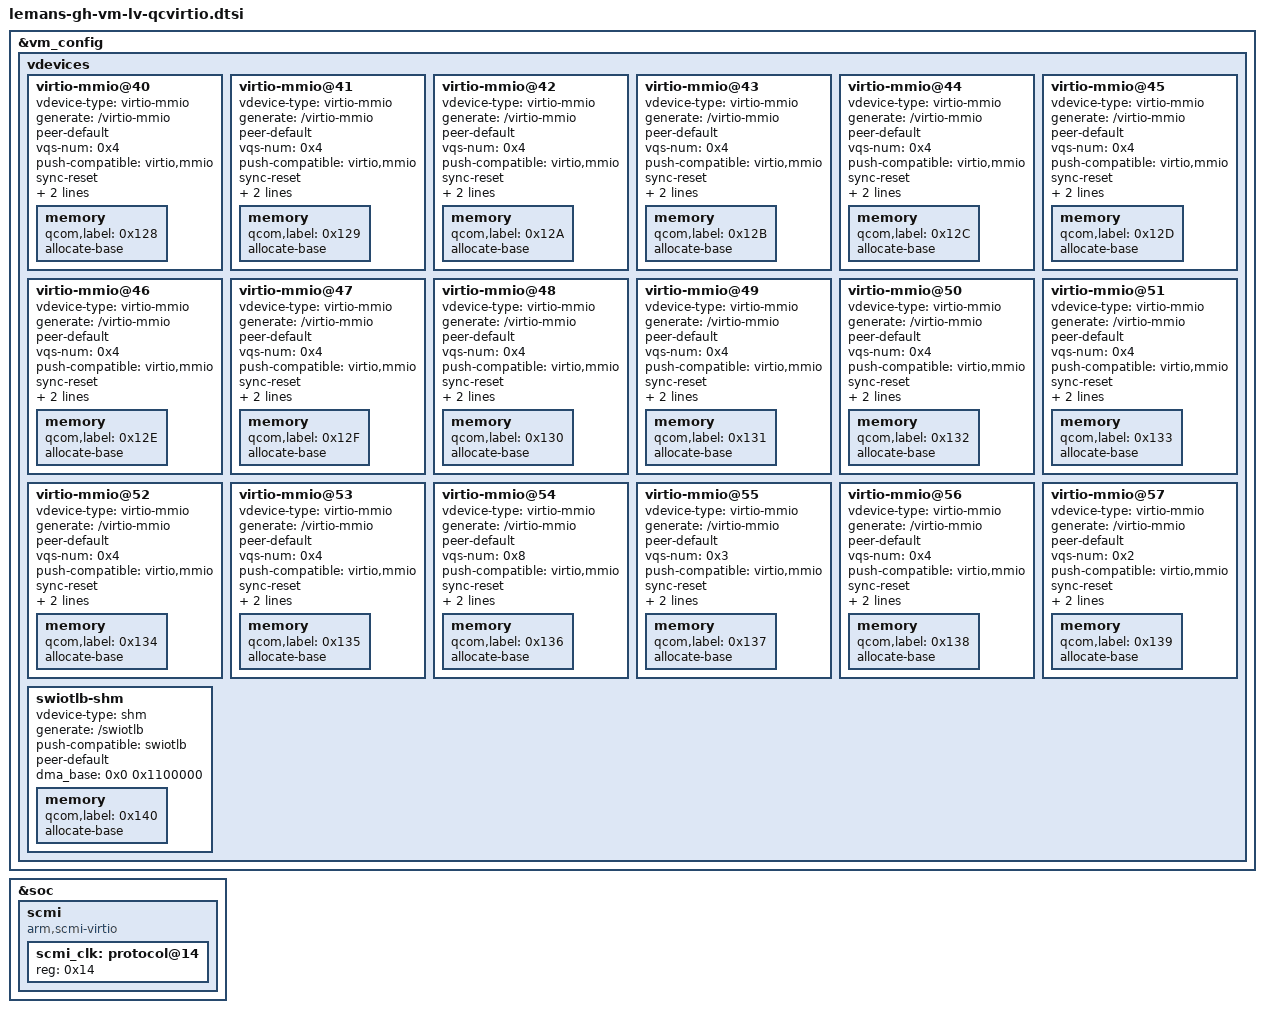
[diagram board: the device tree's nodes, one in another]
// SPDX-License-Identifier: BSD-3-Clause
/*
 * Copyright (c) Qualcomm Technologies, Inc. and/or its subsidiaries.
 */

&vm_config {
	vdevices {
		/* qcvirtio-input */
		virtio-mmio@40 {
			vdevice-type = "virtio-mmio";
			generate = "/virtio-mmio";
			peer-default;
			vqs-num = <0x4>;
			push-compatible = "virtio,mmio";
			sync-reset;
			dma-coherent;
			dma_base = <0x0 0x1E4000>;
			memory {
				qcom,label = <0x128>;
				#address-cells = <0x2>;
				allocate-base;
			};
		};

		/* qcvirtio-rng */
		virtio-mmio@41 {
			vdevice-type = "virtio-mmio";
			generate = "/virtio-mmio";
			peer-default;
			vqs-num = <0x4>;
			push-compatible = "virtio,mmio";
			sync-reset;
			dma-coherent;
			dma_base = <0x0 0x1E8000>;
			memory {
				qcom,label = <0x129>;
				#address-cells = <0x2>;
				allocate-base;
			};
		};

		/* qcvirtio-vsock */
		virtio-mmio@42 {
			vdevice-type = "virtio-mmio";
			generate = "/virtio-mmio";
			peer-default;
			vqs-num = <0x4>;
			push-compatible = "virtio,mmio";
			sync-reset;
			dma-coherent;
			dma_base = <0x0 0x1EC000>;
			memory {
				qcom,label = <0x12A>;
				#address-cells = <0x2>;
				allocate-base;
			};
		};

		/* qcvirtio-gpio */
		virtio-mmio@43 {
			vdevice-type = "virtio-mmio";
			generate = "/virtio-mmio";
			peer-default;
			vqs-num = <0x4>;
			push-compatible = "virtio,mmio";
			sync-reset;
			dma-coherent;
			dma_base = <0x0 0x1F0000>;
			memory {
				qcom,label = <0x12B>;
				#address-cells = <0x2>;
				allocate-base;
			};
		};

		/* qcvirtio-scmi */
		virtio-mmio@44 {
			vdevice-type = "virtio-mmio";
			generate = "/virtio-mmio";
			peer-default;
			vqs-num = <0x4>;
			push-compatible = "virtio,mmio";
			sync-reset;
			dma-coherent;
			dma_base = <0x0 0x1F4000>;
			memory {
				qcom,label = <0x12C>;
				#address-cells = <0x2>;
				allocate-base;
			};
		};

		/* qcvirtio-spi */
		virtio-mmio@45 {
			vdevice-type = "virtio-mmio";
			generate = "/virtio-mmio";
			peer-default;
			vqs-num = <0x4>;
			push-compatible = "virtio,mmio";
			sync-reset;
			dma-coherent;
			dma_base = <0x0 0x1F8000>;
			memory {
				qcom,label = <0x12D>;
				#address-cells = <0x2>;
				allocate-base;
			};
		};

		/* qcvirtio-can */
		virtio-mmio@46 {
			vdevice-type = "virtio-mmio";
			generate = "/virtio-mmio";
			peer-default;
			vqs-num = <0x4>;
			push-compatible = "virtio,mmio";
			sync-reset;
			dma-coherent;
			dma_base = <0x0 0x1FC000>;
			memory {
				qcom,label = <0x12E>;
				#address-cells = <0x2>;
				allocate-base;
			};
		};

		/* qcvirtio-bt */
		virtio-mmio@47 {
			vdevice-type = "virtio-mmio";
			generate = "/virtio-mmio";
			peer-default;
			vqs-num = <0x4>;
			push-compatible = "virtio,mmio";
			sync-reset;
			dma-coherent;
			dma_base = <0x0 0x200000>;
			memory {
				qcom,label = <0x12F>;
				#address-cells = <0x2>;
				allocate-base;
			};
		};

		/* qcvirtio-camera */
		virtio-mmio@48 {
			vdevice-type = "virtio-mmio";
			generate = "/virtio-mmio";
			peer-default;
			vqs-num = <0x4>;
			push-compatible = "virtio,mmio";
			sync-reset;
			dma-coherent;
			dma_base = <0x0 0x204000>;
			memory {
				qcom,label = <0x130>;
				#address-cells = <0x2>;
				allocate-base;
			};
		};


		/* qcvirtio-i2c */
		virtio-mmio@49 {
			vdevice-type = "virtio-mmio";
			generate = "/virtio-mmio";
			peer-default;
			vqs-num = <0x4>;
			push-compatible = "virtio,mmio";
			sync-reset;
			dma-coherent;
			dma_base = <0x0 0x208000>;
			memory {
				qcom,label = <0x131>;
				#address-cells = <0x2>;
				allocate-base;
			};
		};

		/* qcvirtio-snd */
		virtio-mmio@50 {
			vdevice-type = "virtio-mmio";
			generate = "/virtio-mmio";
			peer-default;
			vqs-num = <0x4>;
			push-compatible = "virtio,mmio";
			sync-reset;
			dma-coherent;
			dma_base = <0x0 0x20C000>;
			memory {
				qcom,label = <0x132>;
				#address-cells = <0x2>;
				allocate-base;
			};
		};


		/* qcvirtio-video-dec */
		virtio-mmio@51 {
			vdevice-type = "virtio-mmio";
			generate = "/virtio-mmio";
			peer-default;
			vqs-num = <0x4>;
			push-compatible = "virtio,mmio";
			sync-reset;
			dma-coherent;
			dma_base = <0x0 0x210000>;
			memory {
				qcom,label = <0x133>;
				#address-cells = <0x2>;
				allocate-base;
			};
		};

		/* qcvirtio-video-enc */
		virtio-mmio@52 {
			vdevice-type = "virtio-mmio";
			generate = "/virtio-mmio";
			peer-default;
			vqs-num = <0x4>;
			push-compatible = "virtio,mmio";
			sync-reset;
			dma-coherent;
			dma_base = <0x0 0x214000>;
			memory {
				qcom,label = <0x134>;
				#address-cells = <0x2>;
				allocate-base;
			};
		};

		/* qcvirtio-rtc */
		virtio-mmio@53 {
			vdevice-type = "virtio-mmio";
			generate = "/virtio-mmio";
			peer-default;
			vqs-num = <0x4>;
			push-compatible = "virtio,mmio";
			sync-reset;
			dma-coherent;
			dma_base = <0x0 0x218000>;
			memory {
				qcom,label = <0x135>;
				#address-cells = <0x2>;
				allocate-base;
			};
		};

		/* qcvirtio-usb */
		virtio-mmio@54 {
			vdevice-type = "virtio-mmio";
			generate = "/virtio-mmio";
			peer-default;
			vqs-num = <0x8>;
			push-compatible = "virtio,mmio";
			sync-reset;
			dma-coherent;
			dma_base = <0x0 0x21C000>;
			memory {
				qcom,label = <0x136>;
				#address-cells = <0x2>;
				allocate-base;
			};
		};

		/* qcvirtio-net */
		virtio-mmio@55 {
			vdevice-type = "virtio-mmio";
			generate = "/virtio-mmio";
			peer-default;
			vqs-num = <0x3>;
			push-compatible = "virtio,mmio";
			sync-reset;
			dma-coherent;
			dma_base = <0x0 0x22C000>;
			memory {
				qcom,label = <0x137>;
				#address-cells = <0x2>;
				allocate-base;
			};
		};

		/* qcvirtio-console */
		virtio-mmio@56 {
			vdevice-type = "virtio-mmio";
			generate = "/virtio-mmio";
			peer-default;
			vqs-num = <0x4>;
			push-compatible = "virtio,mmio";
			sync-reset;
			dma-coherent;
			dma_base = <0x0 0x234000>;
			memory {
				qcom,label = <0x138>;
				#address-cells = <0x2>;
				allocate-base;
			};
		};

		/* reserved */
		virtio-mmio@57 {
			vdevice-type = "virtio-mmio";
			generate = "/virtio-mmio";
			peer-default;
			vqs-num = <0x2>;
			push-compatible = "virtio,mmio";
			sync-reset;
			dma-coherent;
			dma_base = <0x0 0x23C000>;
			memory {
				qcom,label = <0x139>;
				#address-cells = <0x2>;
				allocate-base;
			};
		};

		swiotlb-shm {
			vdevice-type = "shm";
			generate = "/swiotlb";
			push-compatible = "swiotlb";
			peer-default;
			dma_base = <0x0 0x1100000>;
			memory {
				qcom,label = <0x140>;
				#address-cells = <0x2>;
				allocate-base;
			};
		};
	};
};

&soc {
	scmi {
		compatible = "arm,scmi-virtio";
		#address-cells = <1>;
		#size-cells = <0>;
		status = "ok";

		scmi_clk: protocol@14 {
			reg = <0x14>;
			#clock-cells = <1>;
		};
	};
};
